# ADC0 register map
Vendor: Texas Instruments
Peripheral module from a debugger description file (folder am437x).
Registers are 32-bit, access not given, no defined reset value unless marked. A register's access mark holds for its fields unless they carry their own. Offsets are as the file gives them; lines under a group give offsets from that group; [hi:lo] are bit positions; {n}, {i} and the like mark numbered series; 'fields as' and 'values as' point back to an identical list; <NAME> marks a mode.

## ADC0
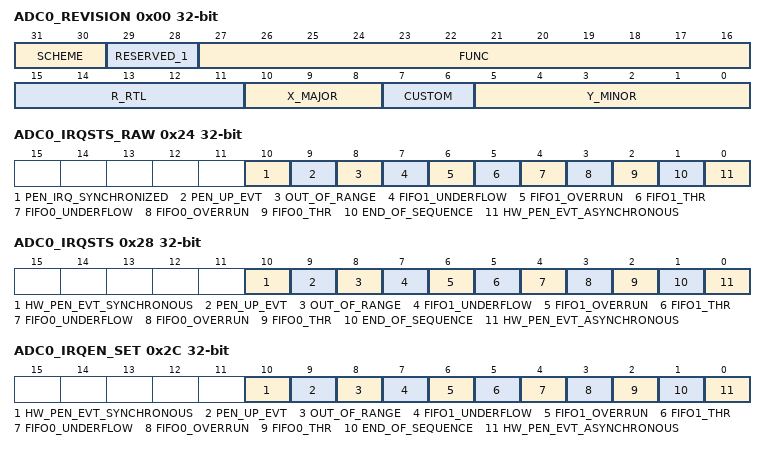
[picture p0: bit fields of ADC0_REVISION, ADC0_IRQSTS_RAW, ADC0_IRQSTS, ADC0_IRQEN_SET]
0x00 ADC0_REVISION ro — Revision Register
  [31:30] SCHEME — Scheme value
  [29:28] RESERVED_1 — Always read as 0. [[br]]Writes have no affect.
  [27:16] FUNC — Function value
  [15:11] R_RTL — RTL Version value
  [10:8] X_MAJOR — Major Revision value
  [7:6] CUSTOM — Custom Revision value
  [5:0] Y_MINOR — Minor Revision value
0x10 ADC0_SYSCONFIG rw — SysConfig Register
  [3:2] IDLEMODE
    3=en_4_0x3 (Smart Idle with Wakeup); 2=en_3_0x2 (Smart-Idle Mode); 1=en_2_0x1 (No Idle Mode (never acknowledges)); 0=en_1_0x0 (Force Idle (always acknowledges))
0x24 ADC0_IRQSTS_RAW rw — IRQ status (unmasked)
  [all] fields
    1=en_4_0x1 (Event pending); 1=en_3_0x1 (Set event (debug)); 0=en_2_0x0 (No event pending); 0=en_1_0x0 (No action)
  [10] PEN_IRQ_SYNCHRONIZED
  [9] PEN_UP_EVT
  [8] OUT_OF_RANGE
  [7] FIFO1_UNDERFLOW
  [6] FIFO1_OVERRUN
  [5] FIFO1_THR
  [4] FIFO0_UNDERFLOW
  [3] FIFO0_OVERRUN
  [2] FIFO0_THR
  [1] END_OF_SEQUENCE
  [0] HW_PEN_EVT_ASYNCHRONOUS
0x28 ADC0_IRQSTS rw — IRQ status (masked)
  [all] fields
    1=en_4_0x1 (Event pending); 1=en_3_0x1 (Clear (raw) event); 0=en_2_0x0 (No action); 0=en_1_0x0 (No (enabled) event pending)
  [10] HW_PEN_EVT_SYNCHRONOUS
  [9] PEN_UP_EVT
  [8] OUT_OF_RANGE
  [7] FIFO1_UNDERFLOW
  [6] FIFO1_OVERRUN
  [5] FIFO1_THR
  [4] FIFO0_UNDERFLOW
  [3] FIFO0_OVERRUN
  [2] FIFO0_THR
  [1] END_OF_SEQUENCE
  [0] HW_PEN_EVT_ASYNCHRONOUS
0x2C ADC0_IRQEN_SET rw — IRQ enable set bits
  [all] fields
    1=en_4_0x1 (Interrupt enabled); 1=en_3_0x1 (Enable interrupt); 0=en_2_0x0 (Interrupt disabled (masked)); 0=en_1_0x0 (No action)
  [10] HW_PEN_EVT_SYNCHRONOUS
  [9] PEN_UP_EVT
  [8] OUT_OF_RANGE
  [7] FIFO1_UNDERFLOW
  [6] FIFO1_OVERRUN
  [5] FIFO1_THR
  [4] FIFO0_UNDERFLOW
  [3] FIFO0_OVERRUN
  [2] FIFO0_THR
  [1] END_OF_SEQUENCE
  [0] HW_PEN_EVT_ASYNCHRONOUS
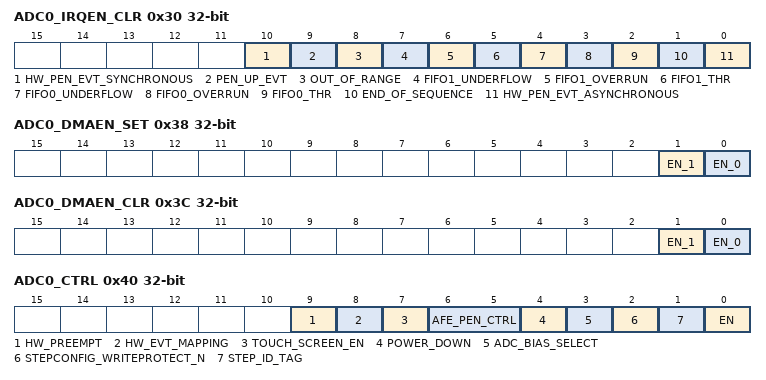
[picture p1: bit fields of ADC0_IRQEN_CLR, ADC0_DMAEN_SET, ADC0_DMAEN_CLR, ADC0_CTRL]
0x30 ADC0_IRQEN_CLR rw — IRQ enable clear bits
  [all] fields
    1=en_4_0x1 (Disable interrupt); 1=en_3_0x1 (Interrupt enabled); 0=en_2_0x0 (Interrupt disabled (masked)); 0=en_1_0x0 (No action)
  [10] HW_PEN_EVT_SYNCHRONOUS
  [9] PEN_UP_EVT
  [8] OUT_OF_RANGE
  [7] FIFO1_UNDERFLOW
  [6] FIFO1_OVERRUN
  [5] FIFO1_THR
  [4] FIFO0_UNDERFLOW
  [3] FIFO0_OVERRUN
  [2] FIFO0_THR
  [1] END_OF_SEQUENCE
  [0] HW_PEN_EVT_ASYNCHRONOUS
0x34 ADC0_IRQWAKEUP rw — IRQ wakeup enable
  [0] WAKEEN0 — Wakeup generation for HW Pen event.
    1=en_2_0x1 (Wakeup enabled); 0=en_1_0x0 (Wakeup disabled)
0x38 ADC0_DMAEN_SET rw — Per-Line DMA set
  [1] EN_1 — Enable DMA request FIFO 1.
    1=en_4_0x1 (Enable DMA line); 1=en_3_0x1 (DMA line enabled); 0=en_2_0x0 (No action); 0=DMA line disabled
  [0] EN_0 — Enable DMA request FIFO 0. [[br]]
    1=en_4_0x1 (Enable DMA line); 1=en_3_0x1 (DMA line enabled); 0=en_2_0x0 (No action); 0=en_1_0x0 (DMA line disabled)
0x3C ADC0_DMAEN_CLR rw — Per-Line DMA clr
  [1] EN_1 — Disable DMA request FIFO 1. [[br]]
    1=en_4_0x1 (Disable DMA line); 1=en_3_0x1 (DMA line enabled); 0=en_2_0x0 (No action); 0=DMA line disabled
  [0] EN_0 — Disable DMA request FIFO 0. [[br]]
    1=en_4_0x1 (Disable DMA line); 1=en_3_0x1 (DMA line enabled); 0=en_2_0x0 (No action); 0=en_1_0x0 (DMA line disabled)
0x40 ADC0_CTRL access per field — Control Register
  [9] HW_PREEMPT rw
    1=en_2_0x1 (SW steps are pre-empted by HW events); 0=en_1_0x0 (SW steps are not pre-empted by HW events)
  [8] HW_EVT_MAPPING rw
    1=en_2_0x1 (Map HW event to HW event input); 0=en_1_0x0 (Map HW event to Pen touch irq (from AFE))
  [7] TOUCH_SCREEN_EN rw
    1=en_2_0x1 (Touchscreen transistors enabled); 0=en_1_0x0 (Touchscreen transistors disabled)
  [6:5] AFE_PEN_CTRL rw — These two bits are sent directly to the AFE Pen Ctrl inputs. [[br]]Bit 6 controls the Wiper touch (5 wire modes). [[br]]Bit 5 controls the X+ touch (4 wire modes). [[br]]User also needs to make sure the ground path is connected properly for pen interrupt to occur (using the StepConfig registers). [[br]]Refer to section 4 interrupts for more information.
  [4] POWER_DOWN rw — ADC Power Down control.
    1=en_2_0x1 (Write 1 to power down AFE (the tsc_adc_ss enable (bit 0) should also be set to off)); 0=en_1_0x0 (AFE is powered up (default))
  [3] ADC_BIAS_SELECT rw — Select Bias to AFE. [[br]]0 = Internal. [[br]]1 = Reserved.
  [2] STEPCONFIG_WRITEPROTECT_N rw — StepConfig_WriteProtect_n is active low.
    1=en_2_0x1 (Step configuration registers are not protected (writable)); 0=en_1_0x0 (Step configuration registers are protected (not writable))
  [1] STEP_ID_TAG rw — Writing 1 to this bit will store the Step ID number with the captured ADC data in the FIFO.
    1=en_2_0x1 (Store the channel ID tag); 0=en_1_0x0 (Write zeroes)
  [0] EN rw — TSC_ADC_SS module enable bit. [[br]]After programming all the steps and configuration registers, write a 1 to this bit to turn on TSC_ADC_SS. [[br]]Writing a 0 will disable the module (after the current conversion).
    1=en_2_0x1 (Enable); 0=en_1_0x0 (Disable)
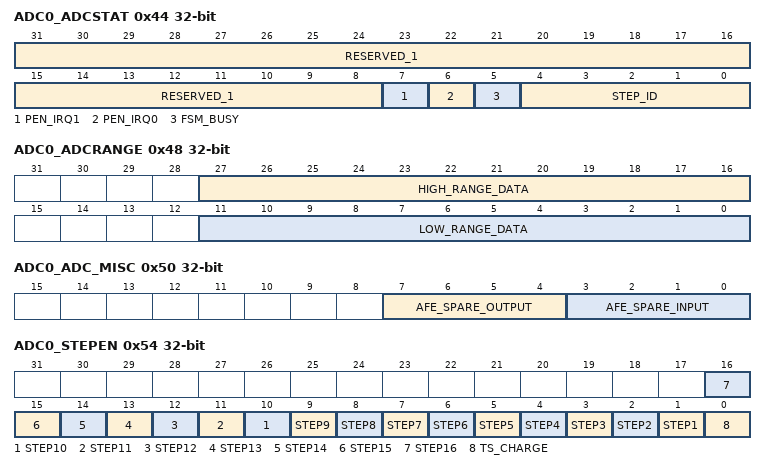
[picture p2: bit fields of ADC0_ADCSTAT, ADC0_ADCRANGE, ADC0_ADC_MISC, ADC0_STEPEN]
0x44 ADC0_ADCSTAT ro — General Status bits for Sequencer Status
  [31:8] RESERVED_1
  [7] PEN_IRQ1 — PEN_IRQ[1] status
  [6] PEN_IRQ0 — PEN_IRQ[0] status
  [5] FSM_BUSY — Status of OCP FSM and ADC FSM. [[br]]
    1=en_2_0x1 (Busy); 0=en_1_0x0 (Idle)
  [4:0] STEP_ID — Encoded values:
    17=en_18_0x11 (Charge); 16=en_17_0x10 (Idle); {v}=en_{v+1}_{0x0+v} (Step {v+1}) (v=0..15)
0x48 ADC0_ADCRANGE access per field — High and Low Range Threshold for ADC Range Check
  [27:16] HIGH_RANGE_DATA rw — Sampled ADC data is compared to this value. [[br]]If the sampled data is greater than the value, then an interrupt is generated.
  [11:0] LOW_RANGE_DATA rw — Sampled ADC data is compared to this value. [[br]]If the sampled data is less than the value, then an interrupt is generated.
0x4C ADC0_ADC_CLKDIV access per field — ADC clock divider register
  [15:0] ADC_CLKDIV rw — The input ADC clock will be divided by this value and sent to the AFE. [[br]]Program to the value minus 1
0x50 ADC0_ADC_MISC access per field — AFE misc debug
  [7:4] AFE_SPARE_OUTPUT ro — Connected to AFE Spare Output pins. [[br]]Reserved in normal operation.
  [3:0] AFE_SPARE_INPUT rw — Connected to AFE Spare Input pins. [[br]]Reserved in normal operation.
0x54 ADC0_STEPEN access per field — Step Enable
  [n] STEP{n} rw (n=1..16) — Enable step {n}
  [0] TS_CHARGE rw — Enable TS Charge step
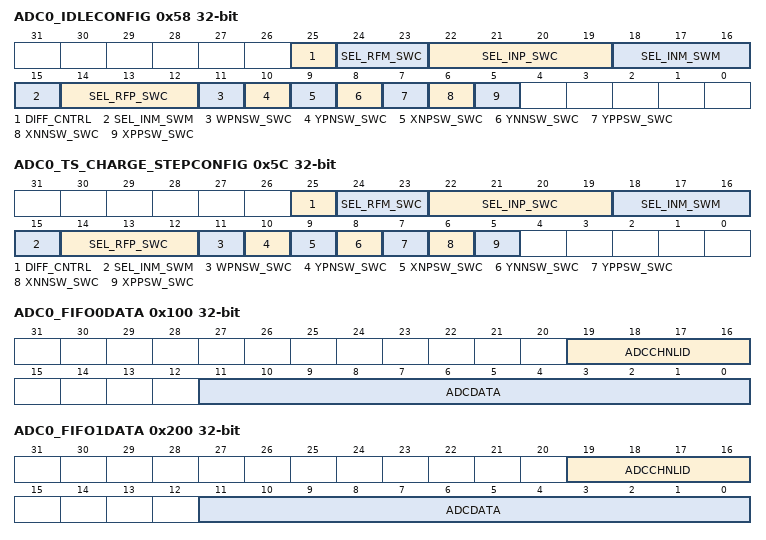
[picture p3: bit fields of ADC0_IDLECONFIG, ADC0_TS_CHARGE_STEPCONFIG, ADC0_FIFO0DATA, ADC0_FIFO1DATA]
0x58 ADC0_IDLECONFIG rw — Idle Step configuration
  [25] DIFF_CNTRL — Differential Control Pin. [[br]]
    1=en_2_0x1 (Differential Pair Enable); 0=en_1_0x0 (Single Ended)
  [24:23] SEL_RFM_SWC — SEL_RFM pins SW configuration.
    3=en_4_0x3 (VREFN); 2=en_3_0x2 (YNLR); 1=en_2_0x1 (XNUR); 0=en_1_0x0 (VSSA_ADC)
  [22:19] SEL_INP_SWC — SEL_INP pins SW configuration. [[br]]Note values 1xxx (binary) = VREFN.
    8=en_9_0x8 (VREFN); {v}=en_{v+1}_{0x0+v} (Channel {v+1}) (v=0..7)
  [18:15] SEL_INM_SWM — SEL_INM pins for neg differential. [[br]]Note all values 1xxx (binary) = VREFN.
    values as SEL_INP_SWC
  [14:12] SEL_RFP_SWC — SEL_RFP pins SW configuration. [[br]]Note all values 1xx (binary) = Reserved.
    3=en_4_0x3 (VREFP); 2=en_3_0x2 (YPLL); 1=en_2_0x1 (XPUL); 0=en_1_0x0 (VDDA_ADC)
  [11] WPNSW_SWC — WPNSW pin SW configuration
  [10] YPNSW_SWC — YPNSW pin SW configuration
  [9] XNPSW_SWC — XNPSW pin SW configuration
  [8] YNNSW_SWC — YNNSW pin SW configuration
  [7] YPPSW_SWC — YPPSW pin SW configuration
  [6] XNNSW_SWC — XNNSW pin SW configuration
  [5] XPPSW_SWC — XPPSW pin SW configuration
0x5C ADC0_TS_CHARGE_STEPCONFIG rw — TS Charge StepConfiguration
  [25] DIFF_CNTRL — Differential Control Pin. [[br]]
    values as ADC0_IDLECONFIG.DIFF_CNTRL
  [24:23] SEL_RFM_SWC — SEL_RFM pins SW configuration.
    values as ADC0_IDLECONFIG.SEL_RFM_SWC
  [22:19] SEL_INP_SWC — SEL_INP pins SW configuration. [[br]]Note all values 1xxx (binary) = VREFN.
    values as ADC0_IDLECONFIG.SEL_INP_SWC
  [18:15] SEL_INM_SWM — SEL_INM pins for neg differential. [[br]]Note all values 1xxx (binary) = VREFN.
    values as ADC0_IDLECONFIG.SEL_INP_SWC
  [14:12] SEL_RFP_SWC — SEL_RFP pins SW configuration. [[br]]Note all values 1xx (binary) = INTREF.
    4=en_5_0x4 (INTREF); 3=en_4_0x3 (VREFP); 2=en_3_0x2 (YPLL); 1=en_2_0x1 (XPUL); 0=en_1_0x0 (VDDA_ADC)
  [11] WPNSW_SWC — WPNSW pin SW configuration
  [10] YPNSW_SWC — YPNSW pin SW configuration
  [9] XNPSW_SWC — XNPSW pin SW configuration
  [8] YNNSW_SWC — YNNSW pin SW configuration
  [7] YPPSW_SWC — YPPSW pin SW configuration
  [6] XNNSW_SWC — XNNSW pin SW configuration
  [5] XPPSW_SWC — XPPSW pin SW configuration
0x60 ADC0_TS_CHARGE_DELAY rw — TS Charge Delay Register
  [17:0] OPENDELAY — Program the # of ADC clock cycles to wait between applying the step configuration registers and going back to the IDLE state. [[br]](Value must be greater than 0.)
{0x64+8i} ADC0_STEPCONFIG_{i} (i=0..15)
{0x68+8i} ADC0_STEPDELAY_{i} (i=0..15)
0xE4 ADC0_FIFOCOUNT_0
0xE8 ADC0_FIFOTHR_0
0xEC ADC0_DMAREQ_0
0xF0 ADC0_FIFOCOUNT_1
0xF4 ADC0_FIFOTHR_1
0xF8 ADC0_DMAREQ_1
0x100 ADC0_FIFO0DATA ro — ADC_ FIFO0 _READ Data
  [19:16] ADCCHNLID — Optional ID tag of channel that captured the data. [[br]]If tag option is disabled, these bits will be 0.
  [11:0] ADCDATA — 12 bit sampled ADC converted data value stored in FIFO 0.
0x200 ADC0_FIFO1DATA ro — ADC FIFO1_READ Data
  [19:16] ADCCHNLID — Optional ID tag of channel that captured the data. [[br]]If tag option is disabled, these bits will be 0.
  [11:0] ADCDATA — 12 bit sampled ADC converted data value stored in FIFO 1.
